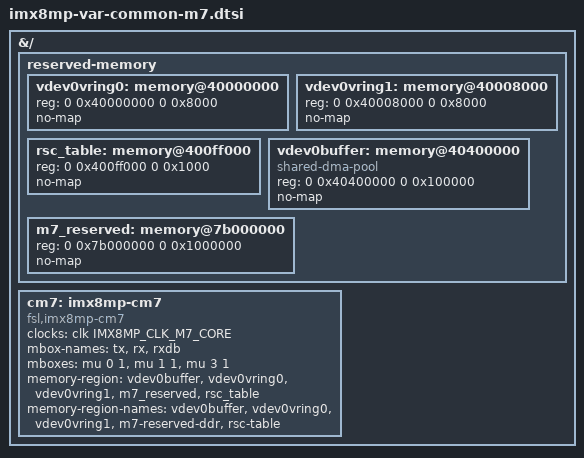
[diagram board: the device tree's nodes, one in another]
// SPDX-License-Identifier: (GPL-2.0 OR MIT)
/*
 * Common Cortex-M7 configuration for Variscite i.MX8M Plus modules
 *
 * Link: https://www.variscite.com/
 *
 * Copyright (C) 2026 Variscite Ltd. - https://www.variscite.com/
 *
 */

#include <dt-bindings/clock/imx8mp-clock.h>

&{/} {
	#address-cells = <2>;
	#size-cells = <2>;

	reserved-memory {
		#address-cells = <2>;
		#size-cells = <2>;
		ranges;

		vdev0vring0: memory@40000000 {
			reg = <0 0x40000000 0 0x8000>;
			no-map;
		};

		vdev0vring1: memory@40008000 {
			reg = <0 0x40008000 0 0x8000>;
			no-map;
		};

		rsc_table: memory@400ff000 {
			reg = <0 0x400ff000 0 0x1000>;
			no-map;
		};

		vdev0buffer: memory@40400000 {
			compatible = "shared-dma-pool";
			reg = <0 0x40400000 0 0x100000>;
			no-map;
		};

		/*
		 * Keep this region aligned with the Cortex-M7 DDR region in the
		 * boot firmware's RDC configuration.
		 *
		 * RDC DDR addresses are encoded as:
		 * (physical address - 0x40000000) >> 1.
		 */
		m7_reserved: memory@7b000000 {
			reg = <0 0x7b000000 0 0x1000000>;
			no-map;
		};
	};

	cm7: imx8mp-cm7 {
		compatible = "fsl,imx8mp-cm7";
		clocks = <&clk IMX8MP_CLK_M7_CORE>;
		mbox-names = "tx", "rx", "rxdb";
		mboxes = <&mu 0 1
			  &mu 1 1
			  &mu 3 1>;
		memory-region = <&vdev0buffer>, <&vdev0vring0>, <&vdev0vring1>,
				<&m7_reserved>, <&rsc_table>;
		memory-region-names = "vdev0buffer", "vdev0vring0", "vdev0vring1",
				      "m7-reserved-ddr", "rsc-table";
	};
};
